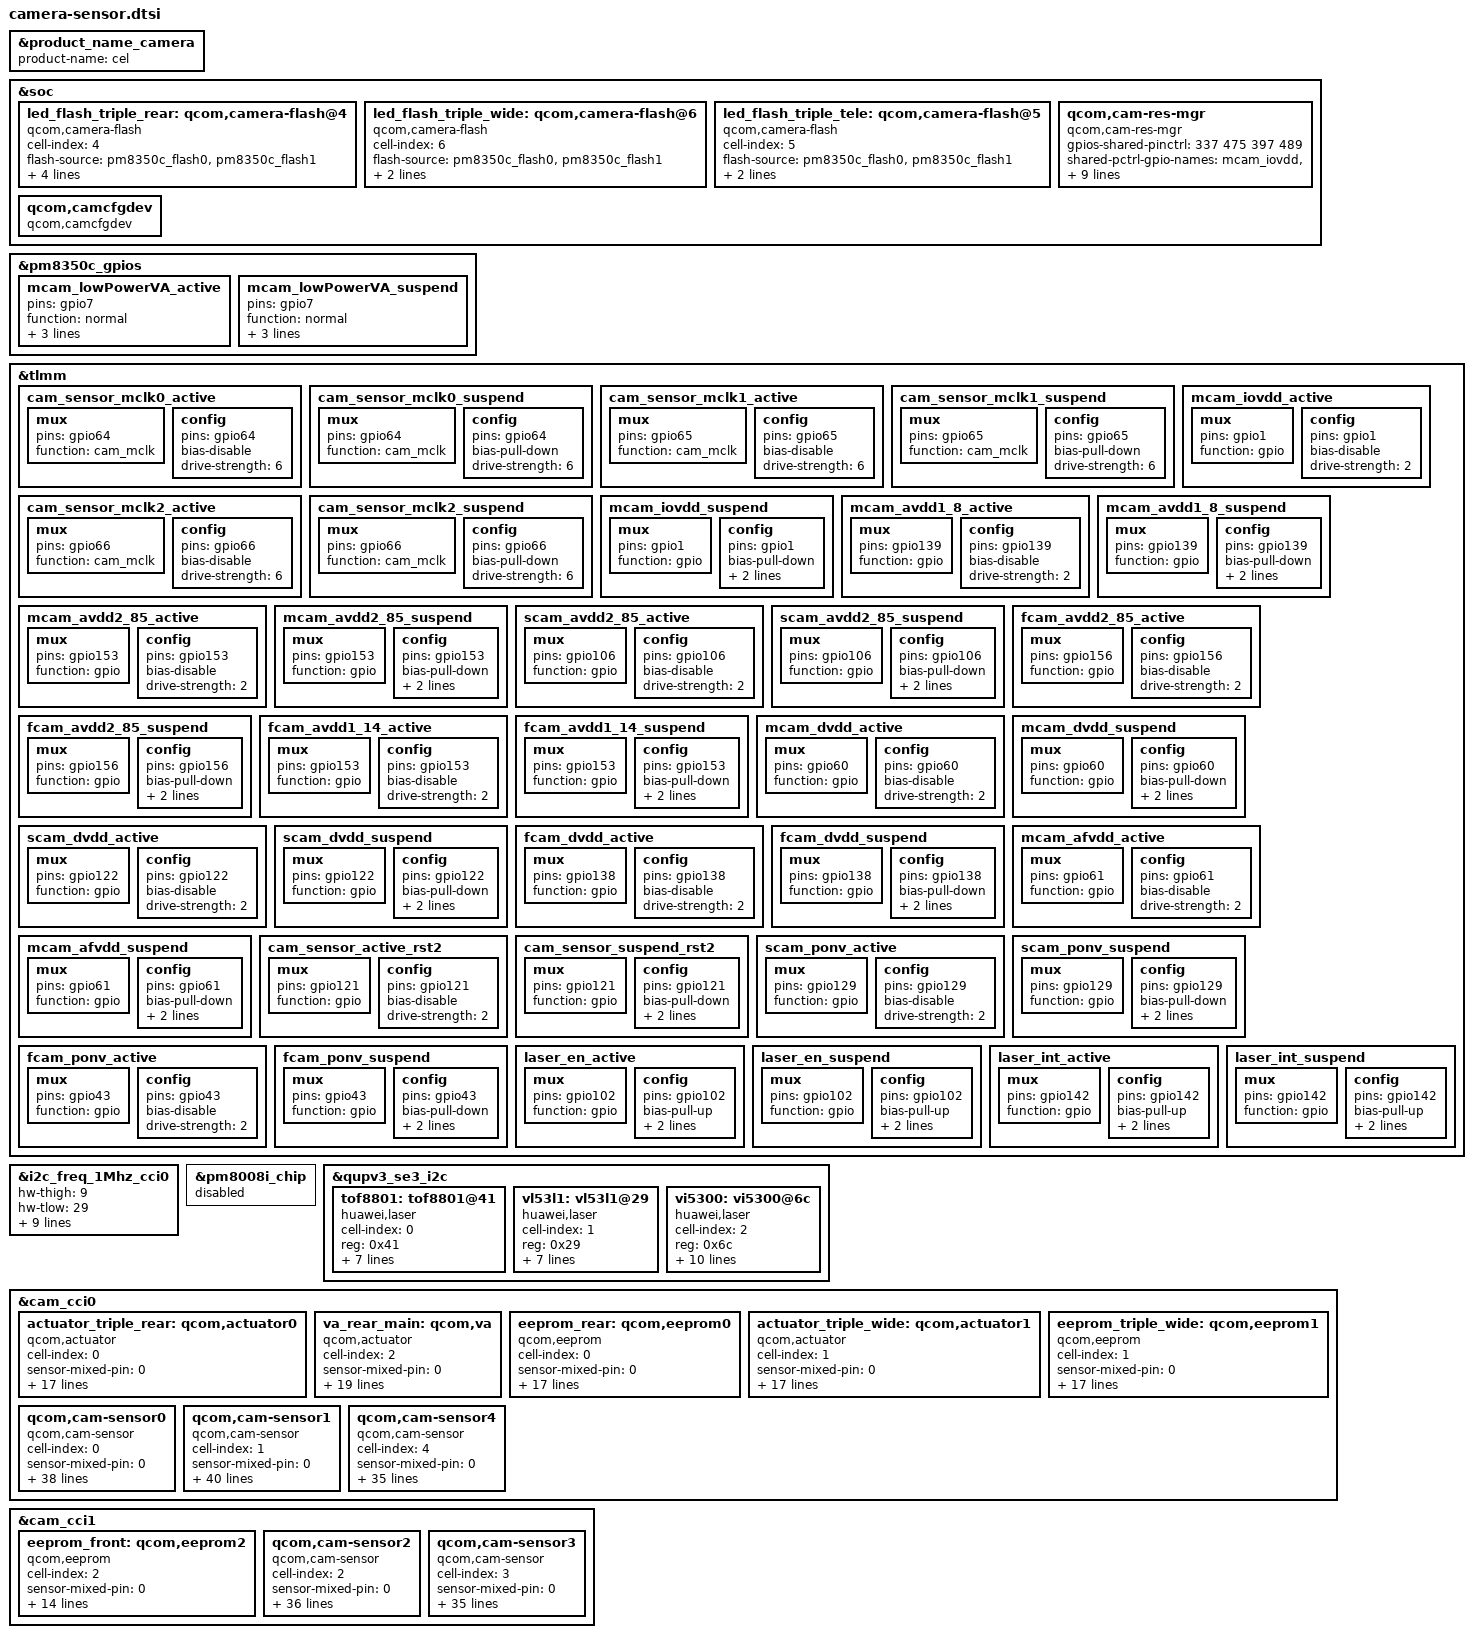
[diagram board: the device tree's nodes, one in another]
#include <dt-bindings/clock/qcom,camcc-yupik.h>

&product_name_camera {
	product-name = "cel";
};

&soc {
	led_flash_triple_rear: qcom,camera-flash@4 {
		cell-index = <4>;
		compatible = "qcom,camera-flash";
		flash-source = <&pm8350c_flash0 &pm8350c_flash1>;
		torch-source = <&pm8350c_torch0 &pm8350c_torch1>;
		switch-source = <&pm8350c_switch2>;
		torch-light-num = <0 1>;
		torch-light-name = "torch-light0", "torch-light1";
		status = "ok";
	};

	led_flash_triple_wide: qcom,camera-flash@6 {
		cell-index = <6>;
		compatible = "qcom,camera-flash";
		flash-source = <&pm8350c_flash0 &pm8350c_flash1>;
		torch-source = <&pm8350c_torch0 &pm8350c_torch1>;
		switch-source = <&pm8350c_switch2>;
		status = "ok";
	};

	led_flash_triple_tele: qcom,camera-flash@5 {
		cell-index = <5>;
		compatible = "qcom,camera-flash";
		flash-source = <&pm8350c_flash0 &pm8350c_flash1>;
		torch-source = <&pm8350c_torch0 &pm8350c_torch1>;
		switch-source = <&pm8350c_switch2>;
		status = "ok";
	};

	qcom,cam-res-mgr {
		compatible = "qcom,cam-res-mgr";
		gpios-shared-pinctrl = <337 475 397 489>;
		shared-pctrl-gpio-names = "mcam_iovdd", "mcam_avdd1_8", "mcam_afvdd", "mcam_avdd2_85";
		pinctrl-names = "mcam_iovdd_active", "mcam_iovdd_suspend",
				"mcam_avdd1_8_active", "mcam_avdd1_8_suspend",
				"mcam_afvdd_active", "mcam_afvdd_suspend",
				"mcam_avdd2_85_active", "mcam_avdd2_85_suspend";
		pinctrl-0 = <&mcam_iovdd_active>;
		pinctrl-1 = <&mcam_iovdd_suspend>;
		pinctrl-2 = <&mcam_avdd1_8_active>;
		pinctrl-3 = <&mcam_avdd1_8_suspend>;
		pinctrl-4 = <&mcam_afvdd_active>;
		pinctrl-5 = <&mcam_afvdd_suspend>;
		pinctrl-6 = <&mcam_avdd2_85_active>;
		pinctrl-7 = <&mcam_avdd2_85_suspend>;
		status = "ok";
	};

	qcom,camcfgdev {
		compatible = "qcom,camcfgdev";
		status = "ok";
	};
};

&pm8350c_gpios {
	mcam_lowPowerVA_active: mcam_lowPowerVA_active {
		pins = "gpio7";
		function = "normal";
		power-source = <1>;
		output-high;
		bias-disable;
	};

	mcam_lowPowerVA_suspend: mcam_lowPowerVA_suspend {
		pins = "gpio7";
		function = "normal";
		power-source = <1>;
		output-low;
		bias-disable;
	};
};

&tlmm {
	cam_sensor_mclk0_active: cam_sensor_mclk0_active {
		/* MCLK0 */
		mux {
			pins = "gpio64";
			function = "cam_mclk";
		};

		config {
			pins = "gpio64";
			bias-disable; /* No PULL */
			drive-strength = <6>; /* 6 MA */
		};
	};

	cam_sensor_mclk0_suspend: cam_sensor_mclk0_suspend {
		/* MCLK0 */
		mux {
			pins = "gpio64";
			function = "cam_mclk";
		};

		config {
			pins = "gpio64";
			bias-pull-down; /* PULL DOWN */
			drive-strength = <6>; /* 6 MA */
		};
	};

	cam_sensor_mclk1_active: cam_sensor_mclk1_active {
		/* MCLK1 */
		mux {
			pins = "gpio65";
			function = "cam_mclk";
		};

		config {
			pins = "gpio65";
			bias-disable; /* No PULL */
			drive-strength = <6>; /* 6 MA */
		};
	};

	cam_sensor_mclk1_suspend: cam_sensor_mclk1_suspend {
		/* MCLK1 */
		mux {
			pins = "gpio65";
			function = "cam_mclk";
		};

		config {
			pins = "gpio65";
			bias-pull-down; /* PULL DOWN */
			drive-strength = <6>; /* 6 MA */
		};
	};

	cam_sensor_mclk2_active: cam_sensor_mclk2_active {
		/* MCLK2 */
		mux {
			pins = "gpio66";
			function = "cam_mclk";
		};

		config {
			pins = "gpio66";
			bias-disable; /* No PULL */
			drive-strength = <6>; /* 6 MA */
		};
	};

	cam_sensor_mclk2_suspend: cam_sensor_mclk2_suspend {
		/* MCLK2 */
		mux {
			pins = "gpio66";
			function = "cam_mclk";
		};

		config {
			pins = "gpio66";
			bias-pull-down; /* PULL DOWN */
			drive-strength = <6>; /* 6 MA */
		};
	};

	mcam_iovdd_active: mcam_iovdd_active {
		mux {
			pins = "gpio1";
			function = "gpio";
		};

		config {
			pins = "gpio1";
			bias-disable; /* No PULL */
			drive-strength = <2>; /* 2 MA */
		};
	};

	mcam_iovdd_suspend: mcam_iovdd_suspend {
		mux {
			pins = "gpio1";
			function = "gpio";
		};

		config {
			pins = "gpio1";
			bias-pull-down; /* PULL DOWN */
			drive-strength = <2>; /* 2 MA */
			output-low;
		};
	};

	mcam_avdd1_8_active: mcam_avdd1_8_active {
		/* mcam_avdd1_8 */
		mux {
			pins = "gpio139";
			function = "gpio";
		};

		config {
			pins = "gpio139";
			bias-disable; /* No PULL */
			drive-strength = <2>; /* 2 MA */
		};
	};

	mcam_avdd1_8_suspend: mcam_avdd1_8_suspend {
		/* mcam_avdd1_8 */
		mux {
			pins = "gpio139";
			function = "gpio";
		};

		config {
			pins = "gpio139";
			bias-pull-down; /* PULL DOWN */
			drive-strength = <2>; /* 2 MA */
			output-low;
		};
	};

	mcam_avdd2_85_active: mcam_avdd2_85_active {
		/* mcam_avdd2_85 */
		mux {
			pins = "gpio153";
			function = "gpio";
		};

		config {
			pins = "gpio153";
			bias-disable; /* No PULL */
			drive-strength = <2>; /* 2 MA */
		};
	};

	mcam_avdd2_85_suspend: mcam_avdd2_85_suspend {
		/* mcam_avdd2_85 */
		mux {
			pins = "gpio153";
			function = "gpio";
		};

		config {
			pins = "gpio153";
			bias-pull-down; /* PULL DOWN */
			drive-strength = <2>; /* 2 MA */
			output-low;
		};
	};

	scam_avdd2_85_active: scam_avdd2_85_active {
		/* scam_avdd2_85 */
		mux {
			pins = "gpio106";
			function = "gpio";
		};

		config {
			pins = "gpio106";
			bias-disable; /* No PULL */
			drive-strength = <2>; /* 2 MA */
		};
	};

	scam_avdd2_85_suspend: scam_avdd2_85_suspend {
		/* scam_avdd2_85 */
		mux {
			pins = "gpio106";
			function = "gpio";
		};

		config {
			pins = "gpio106";
			bias-pull-down; /* PULL DOWN */
			drive-strength = <2>; /* 2 MA */
			output-low;
		};
	};

	fcam_avdd2_85_active: fcam_avdd2_85_active {
		/* fcam_avdd2_85 */
		mux {
			pins = "gpio156";
			function = "gpio";
		};

		config {
			pins = "gpio156";
			bias-disable; /* No PULL */
			drive-strength = <2>; /* 2 MA */
		};
	};

	fcam_avdd2_85_suspend: fcam_avdd2_85_suspend {
		/* fcam_avdd2_85 */
		mux {
			pins = "gpio156";
			function = "gpio";
		};

		config {
			pins = "gpio156";
			bias-pull-down; /* PULL DOWN */
			drive-strength = <2>; /* 2 MA */
			output-low;
		};
	};

	fcam_avdd1_14_active: fcam_avdd1_14_active {
		/* fcam_avdd2_85 */
		mux {
			pins = "gpio153";
			function = "gpio";
		};

		config {
			pins = "gpio153";
			bias-disable; /* No PULL */
			drive-strength = <2>; /* 2 MA */
		};
	};

	fcam_avdd1_14_suspend: fcam_avdd1_14_suspend {
		/* fcam_avdd2_85 */
		mux {
			pins = "gpio153";
			function = "gpio";
		};

		config {
			pins = "gpio153";
			bias-pull-down; /* PULL DOWN */
			drive-strength = <2>; /* 2 MA */
			output-low;
		};
	};

	mcam_dvdd_active: mcam_dvdd_active {
		mux {
			pins = "gpio60";
			function = "gpio";
		};

		config {
			pins = "gpio60";
			bias-disable; /* No PULL */
			drive-strength = <2>; /* 2 MA */
		};
	};

	mcam_dvdd_suspend: mcam_dvdd_suspend {
		mux {
			pins = "gpio60";
			function = "gpio";
		};

		config {
			pins = "gpio60";
			bias-pull-down; /* PULL DOWN */
			drive-strength = <2>; /* 2 MA */
			output-low;
		};
	};

	scam_dvdd_active: scam_dvdd_active {
		mux {
			pins = "gpio122";
			function = "gpio";
		};

		config {
			pins = "gpio122";
			bias-disable; /* No PULL */
			drive-strength = <2>; /* 2 MA */
		};
	};

	scam_dvdd_suspend: scam_dvdd_suspend {
		mux {
			pins = "gpio122";
			function = "gpio";
		};

		config {
			pins = "gpio122";
			bias-pull-down; /* PULL DOWN */
			drive-strength = <2>; /* 2 MA */
			output-low;
		};
	};

	fcam_dvdd_active: fcam_dvdd_active {
		mux {
			pins = "gpio138";
			function = "gpio";
		};

		config {
			pins = "gpio138";
			bias-disable; /* No PULL */
			drive-strength = <2>; /* 2 MA */
		};
	};

	fcam_dvdd_suspend: fcam_dvdd_suspend {
		mux {
			pins = "gpio138";
			function = "gpio";
		};

		config {
			pins = "gpio138";
			bias-pull-down; /* PULL DOWN */
			drive-strength = <2>; /* 2 MA */
			output-low;
		};
	};

	mcam_afvdd_active: mcam_afvdd_active {
		mux {
			pins = "gpio61";
			function = "gpio";
		};

		config {
			pins = "gpio61";
			bias-disable; /* No PULL */
			drive-strength = <2>; /* 2 MA */
		};
	};

	mcam_afvdd_suspend: mcam_afvdd_suspend {
		mux {
			pins = "gpio61";
			function = "gpio";
		};

		config {
			pins = "gpio61";
			bias-pull-down; /* PULL DOWN */
			drive-strength = <2>; /* 2 MA */
			output-low;
		};
	};

	cam_sensor_active_rst2: cam_sensor_active_rst2 {
		/* RESET 2 */
		mux {
			pins = "gpio121";
			function = "gpio";
		};

		config {
			pins = "gpio121";
			bias-disable; /* No PULL */
			drive-strength = <2>; /* 2 MA */
		};
	};

	cam_sensor_suspend_rst2: cam_sensor_suspend_rst2 {
		/* RESET 2 */
		mux {
			pins = "gpio121";
			function = "gpio";
		};

		config {
			pins = "gpio121";
			bias-pull-down; /* PULL DOWN */
			drive-strength = <2>; /* 2 MA */
			output-low;
		};
	};

	scam_ponv_active: scam_ponv_active {
		/* fcam ponv */
		mux {
			pins = "gpio129";
			function = "gpio";
		};

		config {
			pins = "gpio129";
			bias-disable; /* No PULL */
			drive-strength = <2>; /* 2 MA */
		};
	};

	scam_ponv_suspend: scam_ponv_suspend {
		/* fcam ponv */
		mux {
			pins = "gpio129";
			function = "gpio";
		};

		config {
			pins = "gpio129";
			bias-pull-down; /* PULL DOWN */
			drive-strength = <2>; /* 2 MA */
			output-low;
		};
	};

	fcam_ponv_active: fcam_ponv_active {
		/* fcam ponv */
		mux {
			pins = "gpio43";
			function = "gpio";
		};

		config {
			pins = "gpio43";
			bias-disable; /* No PULL */
			drive-strength = <2>; /* 2 MA */
		};
	};

	fcam_ponv_suspend: fcam_ponv_suspend {
		/* fcam ponv */
		mux {
			pins = "gpio43";
			function = "gpio";
		};

		config {
			pins = "gpio43";
			bias-pull-down; /* PULL DOWN */
			drive-strength = <2>; /* 2 MA */
			output-low;
		};
	};

	laser_en_active: laser_en_active {
		/* laser en pin */
		mux {
			pins = "gpio102";
			function = "gpio";
		};

		config {
			pins = "gpio102";
			bias-pull-up; /* PULL UP */
			drive-strength = <2>; /* 2 MA */
			input-enable;
		};
	};

	laser_en_suspend: laser_en_suspend {
		/* laser en pin */
		mux {
			pins = "gpio102";
			function = "gpio";
		};

		config {
			pins = "gpio102";
			bias-pull-up; /* PULL UP */
			drive-strength = <2>; /* 2 MA */
			input-enable;
		};
	};

	laser_int_active: laser_int_active {
		/* laser int pin */
		mux {
			pins = "gpio142";
			function = "gpio";
		};

		config {
			pins = "gpio142";
			bias-pull-up; /* PULL UP */
			drive-strength = <2>; /* 2 MA */
			input-enable;
		};
	};

	laser_int_suspend: laser_int_suspend {
		/* laser int pin */
		mux {
			pins = "gpio142";
			function = "gpio";
		};

		config {
			pins = "gpio142";
			bias-pull-up; /* PULL UP */
			drive-strength = <2>; /* 2 MA */
			input-enable;
		};
	};
};

&i2c_freq_1Mhz_cci0 {
	hw-thigh = <9>;
	hw-tlow = <29>;
	hw-tsu-sto = <17>;
	hw-tsu-sta = <18>;
	hw-thd-dat = <16>;
	hw-thd-sta = <15>;
	hw-tbuf = <24>;
	hw-scl-stretch-en = <1>;
	hw-trdhld = <3>;
	hw-tsp = <3>;
	cci-clk-src = <37500000>;
	status = "ok";
};

&pm8008i_chip {
        status = "disabled";
};

/* laser */
&qupv3_se3_i2c {
	status = "ok";
	#address-cells = <1>;
	#size-cells = <0>;

	tof8801: tof8801@41 {
		cell-index = <0>;
		compatible = "huawei,laser";
		reg = <0x41>;
		vdd_ana-supply = <&pm8350c_l7>;
		gpios = <&tlmm 102 0>,
			<&tlmm 142 0>;
		pinctrl-names = "laser_int_active", "laser_en_active";
		pinctrl-0 = <&laser_int_active>;
		pinctrl-1 = <&laser_en_active>;
		gpio-req-tbl-num = <0>;
		gpio-req-tbl-flags = <0>;
		gpio-req-tbl-label = "CAM_VAF0";
		status = "ok";
	};

	vl53l1: vl53l1@29 {
		cell-index = <1>;
		compatible = "huawei,laser";
		reg = <0x29>;
		vdd_ana-supply = <&pm8350c_l7>;
		gpios = <&tlmm 102 0>,
			<&tlmm 142 0>;
		pinctrl-names = "laser_int_active", "laser_en_active";
		pinctrl-0 = <&laser_int_active>;
		pinctrl-1 = <&laser_en_active>;
		gpio-req-tbl-num = <0>;
		gpio-req-tbl-flags = <0>;
		gpio-req-tbl-label = "CAM_VAF0";
		status = "ok";
	};

	vi5300: vi5300@6c {
		cell-index = <2>;
		compatible = "huawei,laser";
		reg = <0x6c>;
		vdd_ana-supply = <&pm8350c_l7>;
		rgltr-min-voltage = <3400000>;
		rgltr-max-voltage = <3400000>;
		rgltr-load-current = <22000>;
		gpios = <&tlmm 102 0>,
			<&tlmm 142 0>;
		pinctrl-names = "laser_int_active", "laser_en_active";
		pinctrl-0 = <&laser_int_active>;
		pinctrl-1 = <&laser_en_active>;
		gpio-req-tbl-num = <0>;
		gpio-req-tbl-flags = <0>;
		gpio-req-tbl-label = "CAM_VAF0";
		status = "ok";
	};
};

/* cci0: i2c0 i2c1 */
&cam_cci0 {

	actuator_triple_rear: qcom,actuator0 {
		cell-index = <0>;
		compatible = "qcom,actuator";
		sensor-mixed-pin = <0>;
		cam_clk-supply = <&cam_cc_titan_top_gdsc>;
		regulator-names = "cam_clk";
		rgltr-cntrl-support;
		5v_boost_support;
		rgltr-min-voltage = <0>;
		rgltr-max-voltage = <0>;
		rgltr-load-current = <0>;
		gpio-no-mux = <0>;
		gpios = <&tlmm 61 0>; /* mcam_afvdd gpio61 */
		gpio-mixed1 = <0>;
		gpio-req-tbl-num = <0>;
		gpio-req-tbl-flags = <0>;
		gpio-req-tbl-label = "CAM_MIXED1";
		cci-master = <0>;
		clocks = <&camcc CAM_CC_MCLK0_CLK>;
		clock-names = "cam_clk";
		clock-cntl-level = "nominal";
		clock-rates = <19200000>;
		status = "ok";
	};

	va_rear_main: qcom,va {
		cell-index = <2>; /* va cell-index is different from the index of all sensors */
		compatible = "qcom,actuator";
		sensor-mixed-pin = <0>;
		cam_clk-supply = <&cam_cc_titan_top_gdsc>;
		regulator-names = "cam_clk";
		rgltr-cntrl-support;
		rgltr-min-voltage = <0>;
		rgltr-max-voltage = <0>;
		rgltr-load-current = <0>;
		gpio-no-mux = <0>;
		pinctrl-names = "cam_default", "cam_suspend";
		pinctrl-0 = <&mcam_lowPowerVA_active>;
		pinctrl-1 = <&mcam_lowPowerVA_suspend>;
		gpios = <&tlmm 61 0>, /* mcam_vavdd (afvdd) gpio61 */
			<&pm8350c_gpios 7 0>; /* lowPowerVA 8350c(7350c) gpio 7 */
		gpio-mixed1 = <0>;
		gpio-vaf-pwctrl = <1>;
		gpio-req-tbl-num = <0 1>;
		gpio-req-tbl-flags = <0 0>;
		gpio-req-tbl-label = "CAM_MIXED1",
					"CAM_VAF_PWCTRL";
		cci-master = <0>;
		clocks = <&camcc CAM_CC_MCLK0_CLK>;
		clock-names = "cam_clk";
		clock-cntl-level = "nominal";
		clock-rates = <19200000>;
		status = "ok";
	};

	eeprom_rear: qcom,eeprom0 {
		cell-index = <0>;
		compatible = "qcom,eeprom";
		sensor-mixed-pin = <0>;
		cam_clk-supply = <&cam_cc_titan_top_gdsc>;
		regulator-names = "cam_clk";
		rgltr-cntrl-support;
		5v_boost_support;
		rgltr-min-voltage = <0>;
		rgltr-max-voltage = <0>;
		rgltr-load-current = <0>;
		gpio-no-mux = <0>;
		gpios = <&tlmm 1 0>; /* mcam_iovdd gpio93 */
		gpio-mixed1 = <0>;
		gpio-req-tbl-num = <0>;
		gpio-req-tbl-flags = <0>;
		gpio-req-tbl-label = "CAM_MIXED1";
		cci-master = <0>; /* i2c0 */
		clocks = <&camcc CAM_CC_MCLK0_CLK>;
		clock-names = "cam_clk";
		clock-cntl-level = "nominal";
		clock-rates = <19200000>;
		status = "ok";
	};

	actuator_triple_wide: qcom,actuator1 {
		cell-index = <1>;
		compatible = "qcom,actuator";
		sensor-mixed-pin = <0>;
		cam_clk-supply = <&cam_cc_titan_top_gdsc>;
		regulator-names = "cam_clk";
		rgltr-cntrl-support;
		5v_boost_support;
		rgltr-min-voltage = <0>;
		rgltr-max-voltage = <0>;
		rgltr-load-current = <0>;
		gpio-no-mux = <0>;
		gpios = <&tlmm 61 0>; /* mcam_afvdd gpio61 */
		gpio-mixed1 = <0>;
		gpio-req-tbl-num = <0>;
		gpio-req-tbl-flags = <0>;
		gpio-req-tbl-label = "CAM_MIXED1";
		cci-master = <1>;
		clocks = <&camcc CAM_CC_MCLK1_CLK>;
		clock-names = "cam_clk";
		clock-cntl-level = "nominal";
		clock-rates = <19200000>;
		status = "ok";
	};

	eeprom_triple_wide: qcom,eeprom1 {
		cell-index = <1>;
		compatible = "qcom,eeprom";
		sensor-mixed-pin = <0>;
		cam_clk-supply = <&cam_cc_titan_top_gdsc>;
		regulator-names = "cam_clk";
		rgltr-cntrl-support;
		5v_boost_support;
		rgltr-min-voltage = <0>;
		rgltr-max-voltage = <0>;
		rgltr-load-current = <0>;
		gpio-no-mux = <0>;
		gpios = <&tlmm 1 0>; /* mcam_iovdd gpio1 */
		gpio-mixed1 = <0>;
		gpio-req-tbl-num = <0>;
		gpio-req-tbl-flags = <0>;
		gpio-req-tbl-label = "CAM_MIXED1";
		cci-master = <1>;
		clocks = <&camcc CAM_CC_MCLK1_CLK>;
		clock-names = "cam_clk";
		clock-cntl-level = "nominal";
		clock-rates = <19200000>;
		status = "ok";
	};

	/* rear main imx766 */
	qcom,cam-sensor0 {
		cell-index = <0>; /* slotId 0 */
		compatible = "qcom,cam-sensor";
		sensor-mixed-pin = <0>;
		csiphy-sd-index = <1>; /* cphy1 */
		sensor-position-roll = <90>;
		sensor-position-pitch = <0>;
		sensor-position-yaw = <180>;
		actuator-src = <&actuator_triple_rear>;
		va-src = <&va_rear_main>;
		eeprom-src = <&eeprom_rear>;
		led-flash-src = <&led_flash_triple_rear>;
		cam_clk-supply = <&cam_cc_titan_top_gdsc>;
		regulator-names = "cam_clk";
		rgltr-cntrl-support;
		rgltr-min-voltage = <0>;
		rgltr-max-voltage = <0>;
		rgltr-load-current = <0>;
		gpio-no-mux = <0>;
		5v_boost_support;
		pinctrl-names = "cam_default", "cam_suspend";
		pinctrl-0 = <&cam_sensor_mclk0_active
				&mcam_dvdd_active
				&cam_sensor_active_rst2>;
		pinctrl-1 = <&cam_sensor_mclk0_suspend
				&mcam_dvdd_suspend
				&cam_sensor_suspend_rst2>;
		gpios = <&tlmm 64 0>, /* mclk0 gpio64 */
			<&tlmm 1 0>, /* iovdd gpio1 */
			<&tlmm 153 0>, /* avdd2.85V gpio153 */
			<&tlmm 139 0>, /* avdd1.8V gpio139 */
			<&tlmm 60 0>, /* dvdd gpio60 */
			<&tlmm 61 0>, /* afvdd gpio61 */
			<&tlmm 121 0>; /* rst gpio121 */
		gpio-mixed1 = <1>;
		gpio-mixed2 = <2>;
		gpio-mixed3 = <3>;
		gpio-mixed4 = <4>;
		gpio-mixed5 = <5>;
		gpio-reset = <6>;
		gpio-req-tbl-num = <0 1 2 3 4 5 6>;
		gpio-req-tbl-flags = <1 0 0 0 0 0 0>;
		gpio-req-tbl-label = "CAMIF_MCLK0",
					"CAM_MIXED1",
					"CAM_MIXED2",
					"CAM_MIXED3",
					"CAM_MIXED4",
					"CAM_MIXED5",
					"CAM_RESET2";
		cci-master = <0>; /* i2c0 */
		clocks = <&camcc CAM_CC_MCLK0_CLK>;
		clock-names = "cam_clk";
		clock-cntl-level = "nominal";
		clock-rates = <19200000>;
		ic_position = <0>; /* CAMERA_POSITION_REAR */
		status = "ok";
	};

	/* rear wide senosr */
	qcom,cam-sensor1 {
		cell-index = <1>;
		compatible = "qcom,cam-sensor";
		sensor-mixed-pin = <0>;
		csiphy-sd-index = <2>;
		sensor-position-roll = <90>;
		sensor-position-pitch = <0>;
		sensor-position-yaw = <180>;
		actuator-src = <&actuator_triple_wide>;
		eeprom-src = <&eeprom_triple_wide>;
		led-flash-src = <&led_flash_triple_wide>;
		cam_clk-supply = <&cam_cc_titan_top_gdsc>;
		regulator-names = "cam_clk";
		rgltr-cntrl-support;
		rgltr-min-voltage = <0>;
		rgltr-max-voltage = <0>;
		rgltr-load-current = <0>;
		gpio-no-mux = <0>;
		5v_boost_support;
		pinctrl-names = "cam_default", "cam_suspend";
		pinctrl-0 = <&cam_sensor_mclk1_active
				&scam_dvdd_active
				&scam_ponv_active
				&cam_sensor_active_rst1>;
		pinctrl-1 = <&cam_sensor_mclk1_suspend
				&scam_dvdd_suspend
				&scam_ponv_suspend
				&cam_sensor_suspend_rst1>;
		gpios = <&tlmm 65 0>, /* mclk1 gpio65 */
			<&tlmm 1 0>, /* iovdd gpio1 */
			<&tlmm 153 0>, /* avdd2.85V gpio153 */
			<&tlmm 139 0>, /* avdd1.8V gpio139 */
			<&tlmm 122 0>, /* dvdd gpio122 */
			<&tlmm 61 0>, /* afvdd gpio61 */
			<&tlmm 129 0>, /* ponv gpio129 */
			<&tlmm 21 0>; /* rst gpio21 */
		gpio-mixed1 = <1>;
		gpio-mixed2 = <2>;
		gpio-mixed3 = <3>;
		gpio-mixed4 = <4>;
		gpio-mixed5 = <5>;
		gpio-custom1 = <6>;
		gpio-reset = <7>;
		gpio-req-tbl-num = <0 1 2 3 4 5 6 7>;
		gpio-req-tbl-flags = <1 0 0 0 0 0 0 0>;
		gpio-req-tbl-label = "CAMIF_MCLK1",
					"CAM_MIXED1",
					"CAM_MIXED2",
					"CAM_MIXED3",
					"CAM_MIXED4",
					"CAM_MIXED5",
					"CAM_CUSTOM1",
					"CAM_RESET1";
		cci-master = <1>;
		clocks = <&camcc CAM_CC_MCLK1_CLK>;
		clock-names = "cam_clk";
		clock-cntl-level = "nominal";
		clock-rates = <19200000>;
		ic_position = <2>; /* CAMERA_POSITION_REAR_SECOND */
		status = "ok";
	};

	/* rear wide swing senosr */
	qcom,cam-sensor4 {
		cell-index = <4>;
		compatible = "qcom,cam-sensor";
		sensor-mixed-pin = <0>;
		csiphy-sd-index = <2>;
		sensor-position-roll = <90>;
		sensor-position-pitch = <0>;
		sensor-position-yaw = <180>;
		cam_clk-supply = <&cam_cc_titan_top_gdsc>;
		regulator-names = "cam_clk";
		rgltr-cntrl-support;
		rgltr-min-voltage = <0>;
		rgltr-max-voltage = <0>;
		rgltr-load-current = <0>;
		gpio-no-mux = <0>;
		pinctrl-names = "cam_default", "cam_suspend";
		pinctrl-0 = <&cam_sensor_mclk1_active
				&scam_dvdd_active
				&scam_ponv_active
				&cam_sensor_active_rst1>;
		pinctrl-1 = <&cam_sensor_mclk1_suspend
				&scam_dvdd_suspend
				&scam_ponv_suspend
				&cam_sensor_suspend_rst1>;
		gpios = <&tlmm 65 0>, /* mclk1 gpio65 */
			<&tlmm 1 0>, /* iovdd gpio1 */
			<&tlmm 153 0>, /* avdd2.85V gpio153 */
			<&tlmm 139 0>, /* avdd1.8V gpio139 */
			<&tlmm 122 0>, /* dvdd gpio122 */
			<&tlmm 129 0>, /* ponv gpio129 */
			<&tlmm 21 0>; /* rst gpio21 */
		gpio-mixed1 = <1>;
		gpio-mixed2 = <2>;
		gpio-mixed3 = <3>;
		gpio-mixed4 = <4>;
		gpio-custom1 = <5>;
		gpio-reset = <6>;
		gpio-req-tbl-num = <0 1 2 3 4 5 6>;
		gpio-req-tbl-flags = <1 0 0 0 0 0 0>;
		gpio-req-tbl-label = "CAMIF_MCLK1",
					"CAM_MIXED1",
					"CAM_MIXED2",
					"CAM_MIXED3",
					"CAM_MIXED4",
					"CAM_CUSTOM1",
					"CAM_RESET1";
		cci-master = <1>;
		clocks = <&camcc CAM_CC_MCLK1_CLK>;
		clock-names = "cam_clk";
		clock-cntl-level = "nominal";
		clock-rates = <19200000>;
		ic_position = <2>; /* CAMERA_POSITION_REAR_SECOND */
		status = "ok";
	};
};

/* cci1: i2c2 i2c3 */
&cam_cci1 {
	eeprom_front: qcom,eeprom2 {
		cell-index = <2>;
		compatible = "qcom,eeprom";
		sensor-mixed-pin = <0>;
		cam_clk-supply = <&cam_cc_titan_top_gdsc>;
		regulator-names = "cam_clk";
		rgltr-cntrl-support;
		5v_boost_support;
		rgltr-min-voltage = <0>;
		rgltr-max-voltage = <0>;
		rgltr-load-current = <0>;
		gpio-no-mux = <0>;
		gpio-req-tbl-num = <0>;
		gpio-req-tbl-flags = <0>;
		cci-master = <1>;
		clocks = <&camcc CAM_CC_MCLK2_CLK>;
		clock-names = "cam_clk";
		clock-cntl-level = "nominal";
		clock-rates = <19200000>;
		status = "ok";
	};

	/* front main senosr */
	qcom,cam-sensor2 {
		cell-index = <2>; /* slotId 2 */
		compatible = "qcom,cam-sensor";
		sensor-mixed-pin = <0>;
		csiphy-sd-index = <3>; /* phy3 */
		sensor-position-roll = <270>;
		sensor-position-pitch = <0>;
		sensor-position-yaw = <0>;
		eeprom-src = <&eeprom_front>;
		cam_clk-supply = <&cam_cc_titan_top_gdsc>;
		regulator-names = "cam_clk";
		rgltr-cntrl-support;
		rgltr-min-voltage = <0>;
		rgltr-max-voltage = <0>;
		rgltr-load-current = <0>;
		gpio-no-mux = <0>;
		5v_boost_support;
		pinctrl-names = "cam_default", "cam_suspend";
		pinctrl-0 = <&cam_sensor_mclk2_active
				&fcam_dvdd_active
				&fcam_ponv_active
				&cam_sensor_active_rst0>;
		pinctrl-1 = <&cam_sensor_mclk2_suspend
				&fcam_dvdd_suspend
				&fcam_ponv_suspend
				&cam_sensor_suspend_rst0>;
		gpios = <&tlmm 66 0>, /* mclk3 gpio66 */
			<&tlmm 153 0>, /* avdd2.85V gpio153 */
			<&tlmm 139 0>, /* avdd1.8V gpio139 */
			<&tlmm 138 0>, /* dvdd gpio138 */
			<&tlmm 43 0>, /* pove gpio43 */
			<&tlmm 20 0>; /* rst gpio20 */
		gpio-mixed1 = <1>;
		gpio-mixed2 = <2>;
		gpio-mixed3 = <3>;
		gpio-custom1 = <4>;
		gpio-reset = <5>;
		gpio-req-tbl-num = <0 1 2 3 4 5>;
		gpio-req-tbl-flags = <1 0 0 0 0 0>;
		gpio-req-tbl-label = "CAMIF_MCLK2",
					"CAM_MIXED1",
					"CAM_MIXED2",
					"CAM_MIXED3",
					"CAM_CUSTOM1",
					"CAM_RESET0";
		cci-master = <1>;
		clocks = <&camcc CAM_CC_MCLK2_CLK>;
		clock-names = "cam_clk";
		clock-cntl-level = "nominal";
		clock-rates = <19200000>;
		ic_position = <1>; /* CAMERA_POSITION_FORE */
		status = "ok";
	};

	/* front swing senosr */
	qcom,cam-sensor3 {
		cell-index = <3>; /* slotId 3 */
		compatible = "qcom,cam-sensor";
		sensor-mixed-pin = <0>;
		csiphy-sd-index = <3>; /* phy3 */
		sensor-position-roll = <270>;
		sensor-position-pitch = <0>;
		sensor-position-yaw = <0>;
		cam_clk-supply = <&cam_cc_titan_top_gdsc>;
		regulator-names = "cam_clk";
		rgltr-cntrl-support;
		rgltr-min-voltage = <0>;
		rgltr-max-voltage = <0>;
		rgltr-load-current = <0>;
		gpio-no-mux = <0>;
		5v_boost_support;
		pinctrl-names = "cam_default", "cam_suspend";
		pinctrl-0 = <&cam_sensor_mclk2_active
				&fcam_dvdd_active
				&fcam_ponv_active
				&cam_sensor_active_rst0>;
		pinctrl-1 = <&cam_sensor_mclk2_suspend
				&fcam_dvdd_suspend
				&fcam_ponv_suspend
				&cam_sensor_suspend_rst0>;
		gpios = <&tlmm 66 0>, /* mclk3 gpio66 */
			<&tlmm 153 0>, /* avdd2.85V gpio153 */
			<&tlmm 139 0>, /* avdd1.8V gpio139 */
			<&tlmm 138 0>, /* dvdd gpio138 */
			<&tlmm 43 0>, /* pove gpio43 */
			<&tlmm 20 0>; /* rst gpio20 */
		gpio-mixed1 = <1>;
		gpio-mixed2 = <2>;
		gpio-mixed3 = <3>;
		gpio-custom1 = <4>;
		gpio-reset = <5>;
		gpio-req-tbl-num = <0 1 2 3 4 5>;
		gpio-req-tbl-flags = <1 0 0 0 0 0>;
		gpio-req-tbl-label = "CAMIF_MCLK2",
					"CAM_MIXED1",
					"CAM_MIXED2",
					"CAM_MIXED3",
					"CAM_CUSTOM1",
					"CAM_RESET0";
		cci-master = <1>;
		clocks = <&camcc CAM_CC_MCLK2_CLK>;
		clock-names = "cam_clk";
		clock-cntl-level = "nominal";
		clock-rates = <19200000>;
		ic_position = <1>; /* CAMERA_POSITION_FORE */
		status = "ok";
	};
};
